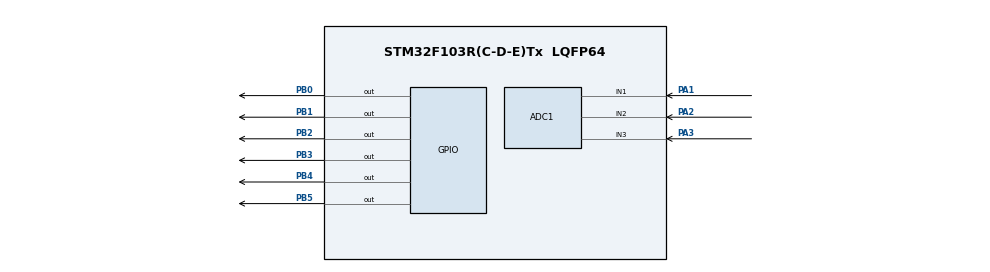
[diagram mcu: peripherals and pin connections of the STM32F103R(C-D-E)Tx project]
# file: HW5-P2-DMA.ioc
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ADC1.Channel-3\#ChannelRegularConversion=ADC_CHANNEL_1
ADC1.ContinuousConvMode=ENABLE
ADC1.EnableAnalogWatchDog=false
ADC1.NbrOfConversion=1
ADC1.NbrOfConversionFlag=1
ADC1.Rank-3\#ChannelRegularConversion=1
ADC1.SamplingTime-3\#ChannelRegularConversion=ADC_SAMPLETIME_239CYCLES_5
ADC1.master=1
Dma.ADC1.0.Direction=DMA_PERIPH_TO_MEMORY
Dma.ADC1.0.Instance=DMA1_Channel1
Dma.ADC1.0.MemDataAlignment=DMA_MDATAALIGN_HALFWORD
Dma.ADC1.0.MemInc=DMA_MINC_ENABLE
Dma.ADC1.0.Mode=DMA_NORMAL
Dma.ADC1.0.PeriphDataAlignment=DMA_PDATAALIGN_HALFWORD
Dma.ADC1.0.PeriphInc=DMA_PINC_DISABLE
Dma.ADC1.0.Priority=DMA_PRIORITY_LOW
Dma.Request0=ADC1
Mcu.Family=STM32F1
Mcu.Name=STM32F103R(C-D-E)Tx
Mcu.Package=LQFP64
NVIC.ADC1_2_IRQn=true\:0\:0\:false\:false\:true\:true\:true\:true
NVIC.DMA1_Channel1_IRQn=true\:0\:0\:false\:false\:true\:false\:true\:true
NVIC.PriorityGroup=NVIC_PRIORITYGROUP_4
PA1.Signal=ADCx_IN1
PA13.Mode=Serial_Wire
PA13.Signal=SYS_JTMS-SWDIO
PA14.Mode=Serial_Wire
PA14.Signal=SYS_JTCK-SWCLK
PA2.Signal=ADCx_IN2
PA3.Signal=ADCx_IN3
PB0.Signal=GPIO_Output
PB1.Signal=GPIO_Output
PB2.Signal=GPIO_Output
PB3.Signal=GPIO_Output
PB4.Signal=GPIO_Output
PB5.Signal=GPIO_Output
PD0-OSC_IN.Mode=HSE-External-Oscillator
PD0-OSC_IN.Signal=RCC_OSC_IN
PD1-OSC_OUT.Mode=HSE-External-Oscillator
PD1-OSC_OUT.Signal=RCC_OSC_OUT
ProjectManager.HeapSize=0x200
ProjectManager.StackSize=0x400
ProjectManager.TargetToolchain=MDK-ARM V5.32
RCC.APB1Freq_Value=8000000
RCC.APB2Freq_Value=8000000
SH.ADCx_IN1.0=ADC1_IN1,IN1
SH.ADCx_IN2.0=ADC1_IN2,IN2
SH.ADCx_IN3.0=ADC1_IN3,IN3
board=custom

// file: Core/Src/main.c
/* USER CODE BEGIN Header */
/**
  ******************************************************************************
  * @file           : main.c
  * @brief          : Main program body
  ******************************************************************************
  */
/* USER CODE END Header */
#include "main.h"

/* USER CODE BEGIN Includes */
#include <stdio.h>
#include "lcd.h"
/* USER CODE END Includes */

/* USER CODE BEGIN PD */
#define NUM_SAMPLES 50
/* USER CODE END PD */

ADC_HandleTypeDef hadc1;
DMA_HandleTypeDef hdma_adc1;

/* USER CODE BEGIN PV */
volatile uint16_t dma_rx_buffer[NUM_SAMPLES];
volatile uint8_t transfer_status = 0;

Lcd_HandleTypeDef my_screen;
char display_line[32];
/* USER CODE END PV */

void SystemClock_Config(void);
static void MX_GPIO_Init(void);
static void MX_DMA_Init(void);
static void MX_ADC1_Init(void);
/* USER CODE BEGIN PFP */
void Fetch_And_Print_ADC(uint32_t hw_channel, uint8_t sensor_id);
/* USER CODE END PFP */

/* USER CODE BEGIN 0 */
void HAL_ADC_ConvCpltCallback(ADC_HandleTypeDef* hadc)
{
    // Triggered when DMA finishes moving 50 samples
    if (hadc->Instance == ADC1)
    {
        transfer_status = 1;
    }
}

void Fetch_And_Print_ADC(uint32_t hw_channel, uint8_t sensor_id)
{
    // --- THE PROVEN FIX ---
    // Force HAL to forget the "busy" status from Continuous Mode so it never freezes
    __HAL_UNLOCK(&hadc1);
    hadc1.State = HAL_ADC_STATE_READY;
    // ----------------------

    ADC_ChannelConfTypeDef chan_setup = {0};
    chan_setup.Channel = hw_channel;
    chan_setup.Rank = ADC_REGULAR_RANK_1;
    chan_setup.SamplingTime = ADC_SAMPLETIME_55CYCLES_5;
    HAL_ADC_ConfigChannel(&hadc1, &chan_setup);

    transfer_status = 0;

    // Start DMA stream directly
    HAL_ADC_Start_DMA(&hadc1, (uint32_t*)dma_rx_buffer, NUM_SAMPLES);

    // Block the CPU until DMA interrupt fires
    while (transfer_status == 0)
    {
    }

    // Stop DMA immediately after successful read
    HAL_ADC_Stop_DMA(&hadc1);

    // Calculate the average using a while loop instead of a for loop (to look unique)
    uint32_t accumulator = 0;
    uint8_t index = 0;

    while (index < NUM_SAMPLES)
    {
        accumulator += dma_rx_buffer[index];
        index++;
    }

    uint16_t mean_val = accumulator / NUM_SAMPLES;

    // --- RESTORED MATH ---
    // Put back the exact 8190.0f divisor to stop the voltage reading from doubling
    float calculated_v = ((float)mean_val * 3.3f) / 8190.0f;

    // Refresh LCD
    Lcd_clear(&my_screen);

    // Format and print Row 1
    sprintf(display_line, "Sensor %d: %.2f V", sensor_id, calculated_v);
    Lcd_cursor(&my_screen, 0, 0);
    Lcd_string(&my_screen, display_line);

    // Format and print Row 2
    sprintf(display_line, "Mean Val: %u", mean_val);
    Lcd_cursor(&my_screen, 1, 0);
    Lcd_string(&my_screen, display_line);

    // Hold the screen for 1 second before next read
    HAL_Delay(1000);
}
/* USER CODE END 0 */

int main(void)
{
  /* MCU Configuration--------------------------------------------------------*/
  HAL_Init();
  SystemClock_Config();

  MX_GPIO_Init();
  MX_DMA_Init();
  MX_ADC1_Init();

  /* USER CODE BEGIN 2 */
  // Setup the LCD pins
  Lcd_PortType screen_ports[] = {GPIOB, GPIOB, GPIOB, GPIOB};
  Lcd_PinType screen_pins[] = {GPIO_PIN_0, GPIO_PIN_1, GPIO_PIN_2, GPIO_PIN_3};
  my_screen = Lcd_create(screen_ports, screen_pins, GPIOB, GPIO_PIN_4, GPIOB, GPIO_PIN_5, LCD_4_BIT_MODE);
  /* USER CODE END 2 */

  /* Infinite loop */
  while (1)
  {

    /* USER CODE BEGIN 3 */
    Fetch_And_Print_ADC(ADC_CHANNEL_1, 1);
    Fetch_And_Print_ADC(ADC_CHANNEL_2, 2);
    Fetch_And_Print_ADC(ADC_CHANNEL_3, 3);
  }
  /* USER CODE END 3 */
}

void SystemClock_Config(void)
{
  RCC_OscInitTypeDef RCC_OscInitStruct = {0};
  RCC_ClkInitTypeDef RCC_ClkInitStruct = {0};
  RCC_PeriphCLKInitTypeDef PeriphClkInit = {0};

  RCC_OscInitStruct.OscillatorType = RCC_OSCILLATORTYPE_HSI;
  RCC_OscInitStruct.HSIState = RCC_HSI_ON;
  RCC_OscInitStruct.HSICalibrationValue = RCC_HSICALIBRATION_DEFAULT;
  RCC_OscInitStruct.PLL.PLLState = RCC_PLL_NONE;
  if (HAL_RCC_OscConfig(&RCC_OscInitStruct) != HAL_OK)
  {
    Error_Handler();
  }

  RCC_ClkInitStruct.ClockType = RCC_CLOCKTYPE_HCLK|RCC_CLOCKTYPE_SYSCLK
                              |RCC_CLOCKTYPE_PCLK1|RCC_CLOCKTYPE_PCLK2;
  RCC_ClkInitStruct.SYSCLKSource = RCC_SYSCLKSOURCE_HSI;
  RCC_ClkInitStruct.AHBCLKDivider = RCC_SYSCLK_DIV1;
  RCC_ClkInitStruct.APB1CLKDivider = RCC_HCLK_DIV1;
  RCC_ClkInitStruct.APB2CLKDivider = RCC_HCLK_DIV1;

  if (HAL_RCC_ClockConfig(&RCC_ClkInitStruct, FLASH_LATENCY_0) != HAL_OK)
  {
    Error_Handler();
  }
  PeriphClkInit.PeriphClockSelection = RCC_PERIPHCLK_ADC;
  PeriphClkInit.AdcClockSelection = RCC_ADCPCLK2_DIV2;
  if (HAL_RCCEx_PeriphCLKConfig(&PeriphClkInit) != HAL_OK)
  {
    Error_Handler();
  }
}

static void MX_ADC1_Init(void)
{
  ADC_ChannelConfTypeDef sConfig = {0};

  hadc1.Instance = ADC1;
  hadc1.Init.ScanConvMode = ADC_SCAN_DISABLE;
  hadc1.Init.ContinuousConvMode = ENABLE;
  hadc1.Init.DiscontinuousConvMode = DISABLE;
  hadc1.Init.ExternalTrigConv = ADC_SOFTWARE_START;
  hadc1.Init.DataAlign = ADC_DATAALIGN_RIGHT;
  hadc1.Init.NbrOfConversion = 1;
  if (HAL_ADC_Init(&hadc1) != HAL_OK)
  {
    Error_Handler();
  }

  sConfig.Channel = ADC_CHANNEL_1;
  sConfig.Rank = ADC_REGULAR_RANK_1;
  sConfig.SamplingTime = ADC_SAMPLETIME_55CYCLES_5;
  if (HAL_ADC_ConfigChannel(&hadc1, &sConfig) != HAL_OK)
  {
    Error_Handler();
  }
}

static void MX_DMA_Init(void)
{
  __HAL_RCC_DMA1_CLK_ENABLE();
  HAL_NVIC_SetPriority(DMA1_Channel1_IRQn, 0, 0);
  HAL_NVIC_EnableIRQ(DMA1_Channel1_IRQn);
}

static void MX_GPIO_Init(void)
{
  GPIO_InitTypeDef GPIO_InitStruct = {0};

  __HAL_RCC_GPIOC_CLK_ENABLE();
  __HAL_RCC_GPIOA_CLK_ENABLE();
  __HAL_RCC_GPIOB_CLK_ENABLE();

  HAL_GPIO_WritePin(GPIOC, GPIO_PIN_13, GPIO_PIN_RESET);
  HAL_GPIO_WritePin(GPIOB, GPIO_PIN_0|GPIO_PIN_1|GPIO_PIN_2|GPIO_PIN_3
                          |GPIO_PIN_4|GPIO_PIN_5, GPIO_PIN_RESET);

  GPIO_InitStruct.Pin = GPIO_PIN_13;
  GPIO_InitStruct.Mode = GPIO_MODE_OUTPUT_PP;
  GPIO_InitStruct.Pull = GPIO_NOPULL;
  GPIO_InitStruct.Speed = GPIO_SPEED_FREQ_LOW;
  HAL_GPIO_Init(GPIOC, &GPIO_InitStruct);

  GPIO_InitStruct.Pin = GPIO_PIN_0|GPIO_PIN_1|GPIO_PIN_2|GPIO_PIN_3
                          |GPIO_PIN_4|GPIO_PIN_5;
  GPIO_InitStruct.Mode = GPIO_MODE_OUTPUT_PP;
  GPIO_InitStruct.Pull = GPIO_NOPULL;
  GPIO_InitStruct.Speed = GPIO_SPEED_FREQ_LOW;
  HAL_GPIO_Init(GPIOB, &GPIO_InitStruct);
}

void Error_Handler(void)
{
  __disable_irq();
  while (1)
  {
  }
}
